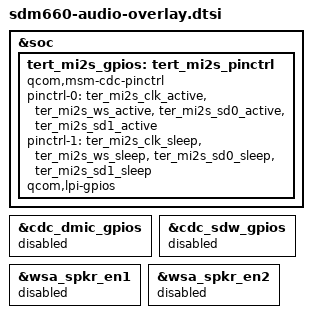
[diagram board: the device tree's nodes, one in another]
/* SPDX-License-Identifier: GPL-2.0 */

&soc {
	tert_mi2s_gpios: tert_mi2s_pinctrl {
		compatible = "qcom,msm-cdc-pinctrl";
		pinctrl-names = "aud_active", "aud_sleep";
		pinctrl-0 = <&ter_mi2s_clk_active &ter_mi2s_ws_active
			&ter_mi2s_sd0_active &ter_mi2s_sd1_active>;
		pinctrl-1 = <&ter_mi2s_clk_sleep &ter_mi2s_ws_sleep
			&ter_mi2s_sd0_sleep &ter_mi2s_sd1_sleep>;
		qcom,lpi-gpios;
	};
};

&cdc_dmic_gpios {
	status = "disabled";
};

&cdc_sdw_gpios {
	status = "disabled";
};

&wsa_spkr_en1 {
	status = "disabled";
};

&wsa_spkr_en2 {
	status = "disabled";
};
